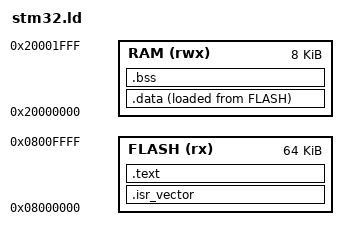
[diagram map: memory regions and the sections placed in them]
/*
 * Linker script for sleepOnExit_experiment
 * Generated by Nazeer Dynamics Project Generator
 *
 * FLASH : program code + read-only data (read-only)
 * RAM   : stack + heap + .bss + initialised .data (read-write)
 *
 * _estack = top of RAM = initial stack pointer value.
 * Cortex-M stacks grow downward, so the stack starts at the top.
 */

ENTRY(Reset_Handler)

MEMORY
{
    FLASH (rx)  : ORIGIN = 0x08000000, LENGTH = 64K
    RAM   (rwx) : ORIGIN = 0x20000000,   LENGTH = 8K
}

_estack = ORIGIN(RAM) + LENGTH(RAM);

SECTIONS
{
    /*
     * .isr_vector -- MUST be first in FLASH.
     * At reset the Cortex-M hardware reads:
     *   word 0: initial stack pointer (_estack)
     *   word 1: address of Reset_Handler
     * from the very start of the FLASH region.
     */
    .isr_vector :
    {
        KEEP(*(.isr_vector))
    } > FLASH

    /*
     * .text -- all executable code and read-only data (.rodata).
     * _etext is used by the startup file to locate where .data is
     * stored in FLASH (its Load Memory Address).
     */
    .text :
    {
        *(.text*)
        *(.glue_7)      /* ARM/Thumb interworking stubs */
        *(.glue_7t)
        *(.eh_frame)
        KEEP(*(.init))
        KEEP(*(.fini))
        *(.rodata*)
        . = ALIGN(4);
        _etext = .;
    } > FLASH

    /*
     * .data -- initialised global and static variables.
     *
     * VMA (Virtual Memory Address) = run-time location in RAM
     * LMA (Load Memory Address)    = stored location in FLASH
     *
     * The startup file copies bytes [_sidata .. _sidata + (_edata-_sdata)]
     * from FLASH into RAM before main() runs.
     */
    .data :
    {
        . = ALIGN(4);
        _sdata = .;         /* start of RAM destination */
        *(.data*)
        . = ALIGN(4);
        _edata = .;         /* end of RAM destination   */
    } > RAM AT > FLASH

    _sidata = LOADADDR(.data);  /* start of FLASH source */

    /*
     * .bss -- uninitialised globals and statics.
     * The linker reserves space in RAM only (nothing stored in FLASH).
     * The startup file zeroes this region (_sbss to _ebss) before main().
     */
    .bss :
    {
        . = ALIGN(4);
        _sbss = .;
        *(.bss*)
        *(COMMON)
        . = ALIGN(4);
        _ebss = .;
    } > RAM
}
